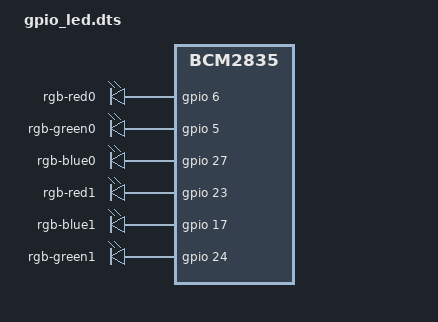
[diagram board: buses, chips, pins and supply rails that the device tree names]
/dts-v1/;
/plugin/;

/ {
    compatible = "brcm,bcm2835";

    fragment@0 {
        target = <&leds>;
        __overlay__ {
            rgb_red_led0: rgb_red0 {
                label = "rgb-red0";
                gpios = <&gpio 6 0>;
                default-state = "off";
            };
            rgb_green_led0: rgb_green0 {
                label = "rgb-green0";
                gpios = <&gpio 5 0>;
                default-state = "off";
            };
            rgb_blue_led0: rgb_blue0 {
                label = "rgb-blue0";
                gpios = <&gpio 27 0>;
                default-state = "off";
            };
            rgb_led_red1: rgb_red1 {
                label = "rgb-red1";
                gpios = <&gpio 23 0>;
                default-state = "off";
            };
            rgb_blue_led1: rgb_blue1 {
                label = "rgb-blue1";
                gpios = <&gpio 17 0>;
                default-state = "off";
            };
            rgb_green_led1: rgb_green1 {
                label = "rgb-green1";
                gpios = <&gpio 24 0>;
                default-state = "off";
            };
        };
    };
};
